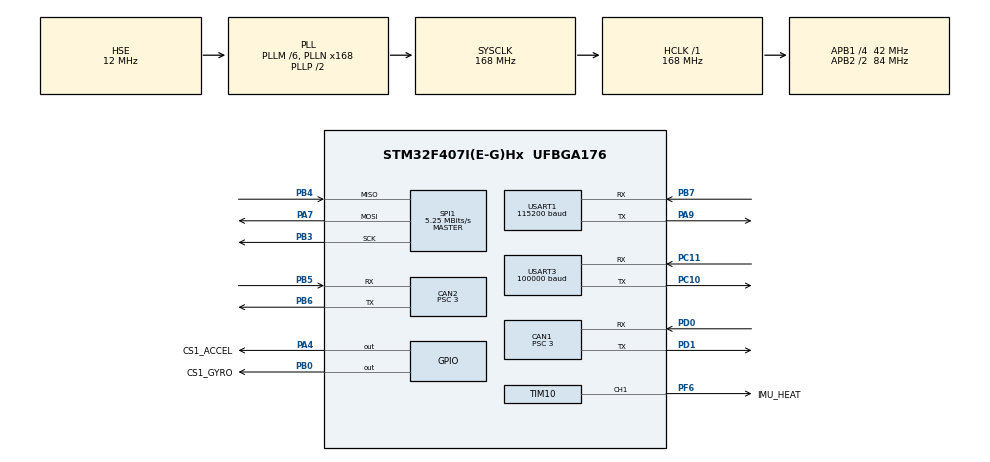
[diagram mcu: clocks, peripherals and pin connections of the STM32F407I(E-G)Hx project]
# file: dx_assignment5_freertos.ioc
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CAN1.ABOM=ENABLE
CAN1.AWUM=ENABLE
CAN1.BS1=CAN_BS1_7TQ
CAN1.BS2=CAN_BS2_6TQ
CAN1.CalculateBaudRate=1000000
CAN1.CalculateTimeBit=1000
CAN1.CalculateTimeQuantum=71.42857142857143
CAN1.Mode=CAN_MODE_NORMAL
CAN1.NART=ENABLE
CAN1.Prescaler=3
CAN1.TXFP=ENABLE
CAN2.BS1=CAN_BS1_7TQ
CAN2.BS2=CAN_BS2_6TQ
CAN2.CalculateBaudRate=1000000
CAN2.CalculateTimeBit=1000
CAN2.CalculateTimeQuantum=71.42857142857143
CAN2.Prescaler=3
Dma.Request0=USART3_RX
Dma.USART3_RX.0.Direction=DMA_PERIPH_TO_MEMORY
Dma.USART3_RX.0.FIFOMode=DMA_FIFOMODE_DISABLE
Dma.USART3_RX.0.Instance=DMA1_Stream1
Dma.USART3_RX.0.MemDataAlignment=DMA_MDATAALIGN_BYTE
Dma.USART3_RX.0.MemInc=DMA_MINC_ENABLE
Dma.USART3_RX.0.Mode=DMA_NORMAL
Dma.USART3_RX.0.PeriphDataAlignment=DMA_PDATAALIGN_BYTE
Dma.USART3_RX.0.PeriphInc=DMA_PINC_DISABLE
Dma.USART3_RX.0.Priority=DMA_PRIORITY_HIGH
FREERTOS.CountingSemaphores01=CAN1CountingSem,3,Dynamic,NULL;CAN2CountingSem,3,Dynamic,NULL
FREERTOS.Queues01=can1_send_fifo,16,can_device_transmit_member,0,Dynamic,NULL,NULL;can2_send_fifo,16,can_device_transmit_member,0,Dynamic,NULL,NULL
FREERTOS.Tasks01=CAN1_Sending_Service,40,256,can1_sending_service,As weak,NULL,Dynamic,NULL,NULL;CAN2_Sending_Service,40,256,can2_sending_service,As weak,NULL,Dynamic,NULL,NULL;DJI_Motor_Service,40,256,DJI_motor_service,As weak,NULL,Dynamic,NULL,NULL;App_Control,32,512,app_control_task,As weak,NULL,Dynamic,NULL,NULL;IMU_Acquire,24,2048,imu_task,As weak,NULL,Dynamic,NULL,NULL
FREERTOS.configMAX_TASK_NAME_LEN=32
FREERTOS.configMINIMAL_STACK_SIZE=128
FREERTOS.configTOTAL_HEAP_SIZE=50000
FREERTOS.configUSE_NEWLIB_REENTRANT=1
Mcu.Family=STM32F4
Mcu.Name=STM32F407I(E-G)Hx
Mcu.Package=UFBGA176
NVIC.CAN1_RX0_IRQn=true\:5\:0\:false\:false\:true\:true\:true\:true\:true
NVIC.CAN1_SCE_IRQn=true\:5\:0\:false\:false\:true\:true\:true\:true\:true
NVIC.CAN1_TX_IRQn=true\:5\:0\:false\:false\:true\:true\:true\:true\:true
NVIC.CAN2_RX1_IRQn=true\:5\:0\:false\:false\:true\:true\:true\:true\:true
NVIC.CAN2_SCE_IRQn=true\:5\:0\:false\:false\:true\:true\:true\:true\:true
NVIC.CAN2_TX_IRQn=true\:5\:0\:false\:false\:true\:true\:true\:true\:true
NVIC.DMA1_Stream1_IRQn=true\:5\:0\:false\:false\:true\:true\:false\:true\:true
NVIC.USART3_IRQn=true\:5\:0\:false\:false\:true\:true\:true\:true\:true
NVIC.PriorityGroup=NVIC_PRIORITYGROUP_4
NVIC.TIM7_IRQn=true\:15\:0\:false\:false\:true\:false\:false\:true\:true
NVIC.TimeBase=TIM7_IRQn
NVIC.TimeBaseIP=TIM7
PA9.Mode=Asynchronous
PA9.Signal=USART1_TX
PB7.Mode=Asynchronous
PB7.Signal=USART1_RX
PC10.Mode=Asynchronous
PC10.Signal=USART3_TX
PC11.Mode=Asynchronous
PC11.Signal=USART3_RX
PA13.Mode=Serial_Wire
PA13.Signal=SYS_JTMS-SWDIO
PA14.Mode=Serial_Wire
PA14.Signal=SYS_JTCK-SWCLK
PB5.Mode=CAN_Activate
PB5.Signal=CAN2_RX
PB6.Mode=CAN_Activate
PB6.Signal=CAN2_TX
PD0.Mode=CAN_Activate
PD0.Signal=CAN1_RX
PD1.Mode=CAN_Activate
PD1.Signal=CAN1_TX
PH0-OSC_IN.Mode=HSE-External-Oscillator
PH0-OSC_IN.Signal=RCC_OSC_IN
PH1-OSC_OUT.Mode=HSE-External-Oscillator
PH1-OSC_OUT.Signal=RCC_OSC_OUT
ProjectManager.HeapSize=0x200
ProjectManager.StackSize=0x400
ProjectManager.TargetToolchain=CMake
RCC.48MHZClocksFreq_Value=84000000
RCC.AHBFreq_Value=168000000
RCC.APB1CLKDivider=RCC_HCLK_DIV4
RCC.APB1Freq_Value=42000000
RCC.APB1TimFreq_Value=84000000
RCC.APB2CLKDivider=RCC_HCLK_DIV2
RCC.APB2Freq_Value=84000000
RCC.APB2TimFreq_Value=168000000
RCC.CortexFreq_Value=168000000
RCC.HCLKFreq_Value=168000000
RCC.HSE_VALUE=12000000
RCC.HSI_VALUE=16000000
RCC.LSE_VALUE=32768
RCC.PLLM=6
RCC.PLLN=168
RCC.PLLSourceVirtual=RCC_PLLSOURCE_HSE
RCC.SYSCLKFreq_VALUE=168000000
RCC.SYSCLKSource=RCC_SYSCLKSOURCE_PLLCLK
RCC.VCOOutputFreq_Value=336000000
USART1.BaudRate=115200
USART1.VirtualMode=VM_ASYNC
USART3.BaudRate=100000
USART3.Parity=PARITY_EVEN
USART3.VirtualMode=VM_ASYNC
USART3.WordLength=WORDLENGTH_9B
VP_FREERTOS_VS_CMSIS_V2.Mode=CMSIS_V2
VP_SYS_VS_tim7.Mode=TIM7
board=custom
PB3.Mode=Full_Duplex_Master
PB3.Signal=SPI1_SCK
PB3.GPIO_PuPd=GPIO_PULLUP
PB4.Mode=Full_Duplex_Master
PB4.Signal=SPI1_MISO
PB4.GPIO_PuPd=GPIO_PULLUP
PA7.Mode=Full_Duplex_Master
PA7.Signal=SPI1_MOSI
PA7.GPIO_PuPd=GPIO_PULLUP
PA4.Signal=GPIO_Output
PA4.PinState=GPIO_PIN_SET
PA4.GPIO_Label=CS1_ACCEL
PA4.GPIO_Speed=GPIO_SPEED_FREQ_HIGH
PB0.Signal=GPIO_Output
PB0.PinState=GPIO_PIN_SET
PB0.GPIO_Label=CS1_GYRO
PB0.GPIO_Speed=GPIO_SPEED_FREQ_HIGH
PF6.Signal=S_TIM10_CH1
PF6.GPIO_PuPd=GPIO_PULLUP
PF6.GPIO_Label=IMU_HEAT
PF6.GPIO_Speed=GPIO_SPEED_FREQ_HIGH
SPI1.VirtualType=VM_MASTER
SPI1.Mode=SPI_MODE_MASTER
SPI1.Direction=SPI_DIRECTION_2LINES
SPI1.BaudRatePrescaler=SPI_BAUDRATEPRESCALER_16
SPI1.CLKPolarity=SPI_POLARITY_HIGH
SPI1.CLKPhase=SPI_PHASE_2EDGE
SPI1.CalculateBaudRate=5.25 MBits/s
TIM10.Channel=TIM_CHANNEL_1
TIM10.Period=2000-1
TIM10.Prescaler=84-1
SH.S_TIM10_CH1.0=TIM10_CH1,PWM Generation1 CH1
VP_TIM10_VS_ClockSourceINT.Mode=Enable_Timer

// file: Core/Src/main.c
/* USER CODE BEGIN Header */
/**
  ******************************************************************************
  * @file           : main.c
  * @brief          : Main program body
  ******************************************************************************
  * @attention
  *
  * Copyright (c) 2026 STMicroelectronics.
  * All rights reserved.
  *
  * This software is licensed under terms that can be found in the LICENSE file
  * in the root directory of this software component.
  * If no LICENSE file comes with this software, it is provided AS-IS.
  *
  ******************************************************************************
  */
/* USER CODE END Header */
#include "main.h"
#include "cmsis_os.h"
#include "can.h"
#include "dma.h"
#include "gpio.h"
#include "usart.h"

/* USER CODE BEGIN Includes */
#include "spi.h"
#include "tim.h"
#include "imu_heater.h"

/* USER CODE END Includes */

void SystemClock_Config(void);
void MX_FREERTOS_Init(void);

int main(void)
{

  /* USER CODE BEGIN 1 */
  __HAL_RCC_SYSCLK_CONFIG(RCC_SYSCLKSOURCE_HSI);
  /* USER CODE END 1 */

  /* MCU Configuration--------------------------------------------------------*/

  /* Reset of all peripherals, Initializes the Flash interface and the Systick. */
  HAL_Init();

  /* Configure the system clock */
  SystemClock_Config();

  /* Initialize all configured peripherals */
  MX_GPIO_Init();
  MX_DMA_Init();
  MX_CAN1_Init();
  MX_CAN2_Init();
  MX_USART1_UART_Init();
  MX_USART3_UART_Init();
  MX_SPI1_Init();
  MX_TIM10_Init();
  /* USER CODE BEGIN 2 */
  /* CAN is started from App_Control after RTOS queues/semaphores exist. */
  /* USER CODE END 2 */

  /* Init scheduler */
  osKernelInitialize();  /* Call init function for freertos objects (in cmsis_os2.c) */
  MX_FREERTOS_Init();

  /* Start scheduler */
  osKernelStart();

  /* We should never get here as control is now taken by the scheduler */

  /* Infinite loop */
  while (1)
  {

  }
}

void SystemClock_Config(void)
{
  RCC_OscInitTypeDef RCC_OscInitStruct = {0};
  RCC_ClkInitTypeDef RCC_ClkInitStruct = {0};

  /** Configure the main internal regulator output voltage
  */
  __HAL_RCC_PWR_CLK_ENABLE();
  __HAL_PWR_VOLTAGESCALING_CONFIG(PWR_REGULATOR_VOLTAGE_SCALE1);

  /** Initializes the RCC Oscillators according to the specified parameters
  * in the RCC_OscInitTypeDef structure.
  */
  RCC_OscInitStruct.OscillatorType = RCC_OSCILLATORTYPE_HSE;
  RCC_OscInitStruct.HSEState = RCC_HSE_ON;
  RCC_OscInitStruct.PLL.PLLState = RCC_PLL_ON;
  RCC_OscInitStruct.PLL.PLLSource = RCC_PLLSOURCE_HSE;
  RCC_OscInitStruct.PLL.PLLM = 6;
  RCC_OscInitStruct.PLL.PLLN = 168;
  RCC_OscInitStruct.PLL.PLLP = RCC_PLLP_DIV2;
  RCC_OscInitStruct.PLL.PLLQ = 4;
  if (HAL_RCC_OscConfig(&RCC_OscInitStruct) != HAL_OK)
  {
    Error_Handler();
  }

  /** Initializes the CPU, AHB and APB buses clocks
  */
  RCC_ClkInitStruct.ClockType = RCC_CLOCKTYPE_HCLK|RCC_CLOCKTYPE_SYSCLK
                              |RCC_CLOCKTYPE_PCLK1|RCC_CLOCKTYPE_PCLK2;
  RCC_ClkInitStruct.SYSCLKSource = RCC_SYSCLKSOURCE_PLLCLK;
  RCC_ClkInitStruct.AHBCLKDivider = RCC_SYSCLK_DIV1;
  RCC_ClkInitStruct.APB1CLKDivider = RCC_HCLK_DIV4;
  RCC_ClkInitStruct.APB2CLKDivider = RCC_HCLK_DIV2;

  if (HAL_RCC_ClockConfig(&RCC_ClkInitStruct, FLASH_LATENCY_5) != HAL_OK)
  {
    Error_Handler();
  }
}

void HAL_TIM_PeriodElapsedCallback(TIM_HandleTypeDef *htim)
{
  if (htim->Instance == TIM7)
  {
    HAL_IncTick();
  }
}

void Error_Handler(void)
{
  /* USER CODE BEGIN Error_Handler_Debug */
  /* Fatal stop: remove heater drive before entering the debug trap. */
  imu_heater_stop();
  __disable_irq();
  while (1)
  {
  }
  /* USER CODE END Error_Handler_Debug */
}
